VERSION ""

NS_ :

BS_:

BU_:

BO_ 2516060670 ParkAssistRequest: 8 Vector__XXX
 SG_ paEnableReq : 2|2@1+ (1,0) [0|3] "" Vector__XXX
 SG_ paAutoReq : 0|2@1+ (1,0) [0|3] "" Vector__XXX

BO_ 2516060414 ParkAssistStatus: 8 Vector__XXX
 SG_ paStatus : 0|2@1+ (1,0) [0|3] "" Vector__XXX

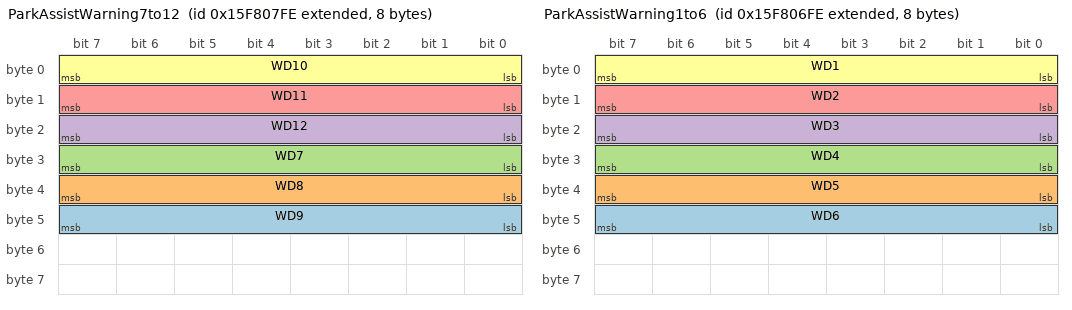
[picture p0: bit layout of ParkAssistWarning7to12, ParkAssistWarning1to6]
BO_ 2516060158 ParkAssistWarning7to12: 8 Vector__XXX
 SG_ WD9 : 40|8@1+ (1,0) [0|255] "" Vector__XXX
 SG_ WD8 : 32|8@1+ (1,0) [0|255] "" Vector__XXX
 SG_ WD7 : 24|8@1+ (1,0) [0|255] "" Vector__XXX
 SG_ WD12 : 16|8@1+ (1,0) [0|255] "" Vector__XXX
 SG_ WD11 : 8|8@1+ (1,0) [0|255] "" Vector__XXX
 SG_ WD10 : 0|8@1+ (1,0) [0|255] "" Vector__XXX

BO_ 2516059902 ParkAssistWarning1to6: 8 Vector__XXX
 SG_ WD6 : 40|8@1+ (1,0) [0|255] "" Vector__XXX
 SG_ WD5 : 32|8@1+ (1,0) [0|255] "" Vector__XXX
 SG_ WD4 : 24|8@1+ (1,0) [0|255] "" Vector__XXX
 SG_ WD3 : 16|8@1+ (1,0) [0|255] "" Vector__XXX
 SG_ WD2 : 8|8@1+ (1,0) [0|255] "" Vector__XXX
 SG_ WD1 : 0|8@1+ (1,0) [0|255] "" Vector__XXX

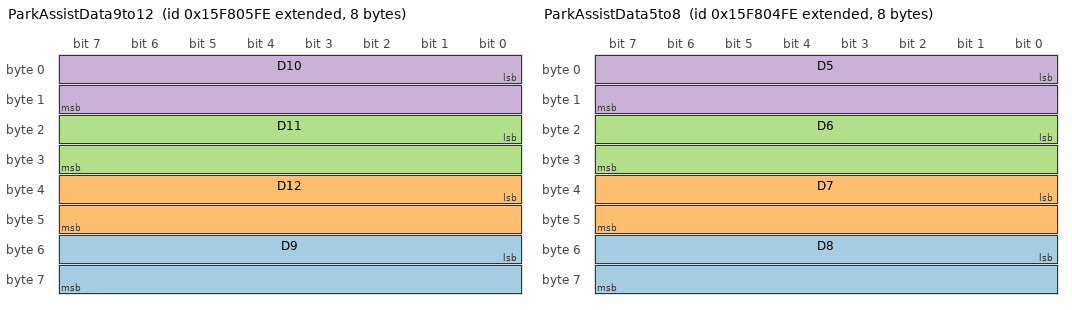
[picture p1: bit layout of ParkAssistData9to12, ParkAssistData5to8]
BO_ 2516059646 ParkAssistData9to12: 8 Vector__XXX
 SG_ D9 : 48|16@1+ (1,0) [0|65535] "mm" Vector__XXX
 SG_ D12 : 32|16@1+ (1,0) [0|65535] "mm" Vector__XXX
 SG_ D11 : 16|16@1+ (1,0) [0|65535] "mm" Vector__XXX
 SG_ D10 : 0|16@1+ (1,0) [0|65535] "mm" Vector__XXX

BO_ 2516059390 ParkAssistData5to8: 8 Vector__XXX
 SG_ D8 : 48|16@1+ (1,0) [0|65535] "mm" Vector__XXX
 SG_ D7 : 32|16@1+ (1,0) [0|65535] "mm" Vector__XXX
 SG_ D6 : 16|16@1+ (1,0) [0|65535] "mm" Vector__XXX
 SG_ D5 : 0|16@1+ (1,0) [0|65535] "mm" Vector__XXX

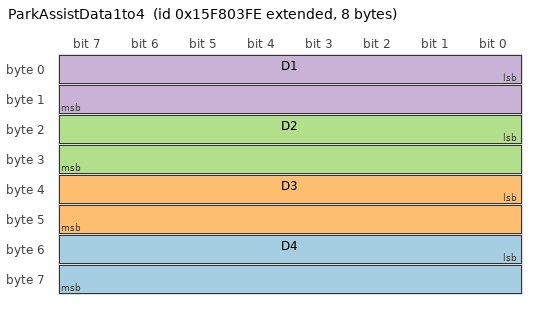
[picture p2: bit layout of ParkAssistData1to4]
BO_ 2516059134 ParkAssistData1to4: 8 Vector__XXX
 SG_ D4 : 48|16@1+ (1,0) [0|65535] "mm" Vector__XXX
 SG_ D3 : 32|16@1+ (1,0) [0|65535] "mm" Vector__XXX
 SG_ D2 : 16|16@1+ (1,0) [0|65535] "mm" Vector__XXX
 SG_ D1 : 0|16@1+ (1,0) [0|65535] "mm" Vector__XXX

CM_ SG_ 2516060158 WD9 "Park Assistant Warning Data for sensor/sector 9";
CM_ SG_ 2516060158 WD8 "Park Assistant Warning Data for sensor/sector 8";
CM_ SG_ 2516060158 WD7 "Park Assistant Warning Data for sensor/sector 6";
CM_ SG_ 2516060158 WD12 "Park Assistant Warning Data for sensor/sector 12";
CM_ SG_ 2516060158 WD11 "Park Assistant Warning Data for sensor/sector 11";
CM_ SG_ 2516060158 WD10 "Park Assistant Warning Data for sensor/sector 10";
CM_ SG_ 2516059902 WD6 "Park Assistant Warning Data for sensor/sector 6";
CM_ SG_ 2516059902 WD5 "Park Assistant Warning Data for sensor/sector 5";
CM_ SG_ 2516059902 WD4 "Park Assistant Warning Data for sensor/sector 4";
CM_ SG_ 2516059902 WD3 "Park Assistant Warning Data for sensor/sector 3";
CM_ SG_ 2516059902 WD2 "Park Assistant Warning Data for sensor/sector 2";
CM_ SG_ 2516059902 WD1 "Park Assistant Warning Data for sensor/sector 1";
BA_DEF_ SG_  "SigType" ENUM  "Default","Range","RangeSigned","ASCII","Discrete","Control","ReferencePGN","DTC","StringDelimiter","StringLength","StringLengthControl","MessageCounter","MessageChecksum";
BA_DEF_ SG_  "GenSigEVName" STRING ;
BA_DEF_ SG_  "GenSigILSupport" ENUM  "No","Yes";
BA_DEF_ SG_  "GenSigSendType" ENUM  "Cyclic","OnWrite","OnWriteWithRepetition","OnChange","OnChangeWithRepetition","IfActive","IfActiveWithRepetition","NoSigSendType";
BA_DEF_ SG_  "GenSigStartValue" INT 0 2147483647;
BA_DEF_ BO_  "GenMsgILSupport" ENUM  "No","Yes";
BA_DEF_ BU_  "NmStationAddress" INT 0 255;
BA_DEF_ BO_  "GenMsgSendType" ENUM  "cyclic","NotUsed","IfActive","NotUsed","NotUsed","NotUsed","NotUsed","NotUsed","noMsgSendType";
BA_DEF_ BO_  "GenMsgRequestable" INT 0 1;
BA_DEF_ BO_  "GenMsgCycleTime" INT 0 3600000;
BA_DEF_  "DBName" STRING ;
BA_DEF_  "BusType" STRING ;
BA_DEF_  "ProtocolType" STRING ;
BA_DEF_ BO_  "VFrameFormat" ENUM  "StandardCAN","ExtendedCAN","reserved","J1939PG";
BA_DEF_DEF_  "SigType" "Default";
BA_DEF_DEF_  "GenSigEVName" "Env@Nodename_@Signame";
BA_DEF_DEF_  "GenSigILSupport" "Yes";
BA_DEF_DEF_  "GenSigSendType" "NoSigSendType";
BA_DEF_DEF_  "GenSigStartValue" 0;
BA_DEF_DEF_  "GenMsgILSupport" "Yes";
BA_DEF_DEF_  "NmStationAddress" 254;
BA_DEF_DEF_  "GenMsgSendType" "noMsgSendType";
BA_DEF_DEF_  "GenMsgRequestable" 1;
BA_DEF_DEF_  "GenMsgCycleTime" 0;
BA_DEF_DEF_  "DBName" "";
BA_DEF_DEF_  "BusType" "CAN";
BA_DEF_DEF_  "ProtocolType" "J1939";
BA_DEF_DEF_  "VFrameFormat" "J1939PG";
BA_ "DBName" "temp";
BA_ "GenMsgSendType" BO_ 2516060670 0;
BA_ "GenMsgCycleTime" BO_ 2516060670 300;
BA_ "GenMsgCycleTime" BO_ 2516060414 300;
BA_ "GenMsgSendType" BO_ 2516060414 0;
BA_ "GenMsgCycleTime" BO_ 2516060158 300;
BA_ "GenMsgSendType" BO_ 2516060158 0;
BA_ "GenMsgCycleTime" BO_ 2516059902 300;
BA_ "GenMsgSendType" BO_ 2516059902 0;
BA_ "GenMsgCycleTime" BO_ 2516059646 300;
BA_ "GenMsgSendType" BO_ 2516059646 0;
BA_ "GenMsgCycleTime" BO_ 2516059390 300;
BA_ "GenMsgSendType" BO_ 2516059390 0;
BA_ "GenMsgCycleTime" BO_ 2516059134 300;
BA_ "GenMsgSendType" BO_ 2516059134 0;
BA_ "GenSigStartValue" SG_ 2516060670 paEnableReq 3;
BA_ "GenSigStartValue" SG_ 2516060670 paAutoReq 3;
BA_ "GenSigStartValue" SG_ 2516060414 paStatus 3;
VAL_ 2516060670 paEnableReq 3 "NotAvailable" 2 "Reserved" 1 "Requested" 0 "NotRequested" ;
VAL_ 2516060670 paAutoReq 3 "NotAvailable" 2 "Reserved" 1 "Requested" 0 "NotRequested" ;
VAL_ 2516060414 paStatus 3 "NotAvailable" 2 "Error" 1 "Active" 0 "NotActive" ;
